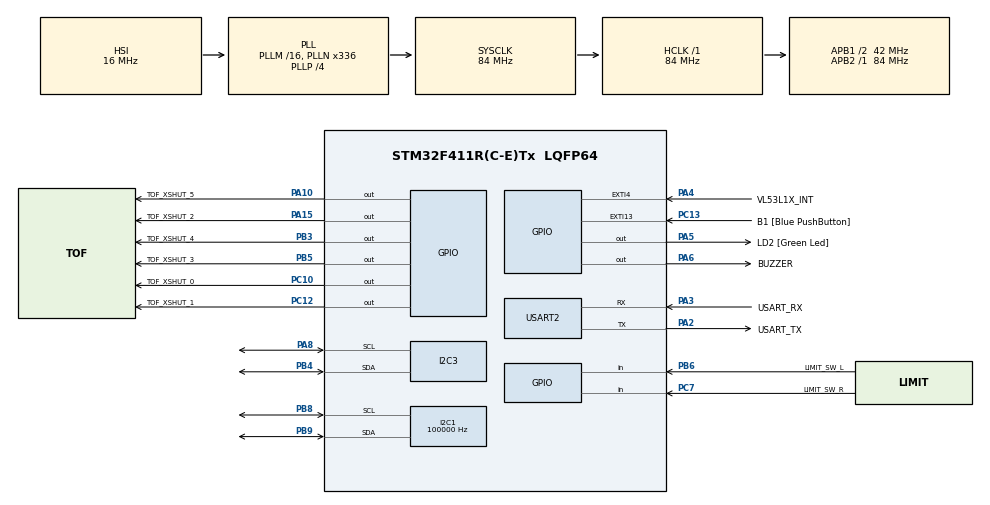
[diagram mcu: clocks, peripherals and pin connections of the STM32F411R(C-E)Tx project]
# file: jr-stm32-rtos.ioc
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Dma.Request0=USART2_RX
Dma.USART2_RX.0.Direction=DMA_PERIPH_TO_MEMORY
Dma.USART2_RX.0.FIFOMode=DMA_FIFOMODE_ENABLE
Dma.USART2_RX.0.FIFOThreshold=DMA_FIFO_THRESHOLD_FULL
Dma.USART2_RX.0.Instance=DMA1_Stream5
Dma.USART2_RX.0.MemBurst=DMA_MBURST_SINGLE
Dma.USART2_RX.0.MemDataAlignment=DMA_MDATAALIGN_BYTE
Dma.USART2_RX.0.MemInc=DMA_MINC_ENABLE
Dma.USART2_RX.0.Mode=DMA_NORMAL
Dma.USART2_RX.0.PeriphBurst=DMA_PBURST_SINGLE
Dma.USART2_RX.0.PeriphDataAlignment=DMA_PDATAALIGN_BYTE
Dma.USART2_RX.0.PeriphInc=DMA_PINC_DISABLE
Dma.USART2_RX.0.Priority=DMA_PRIORITY_LOW
FREERTOS.Tasks01=taskChassis,0,128,chassis_task,Default,NULL,Dynamic,NULL,NULL;taskTOF,0,128,tof_task,Default,NULL,Dynamic,NULL,NULL;taskComm,0,128,comm_task,Default,NULL,Dynamic,NULL,NULL
I2C1.ClockSpeed=100000
I2C1.I2C_Mode=I2C_Standard
Mcu.Family=STM32F4
Mcu.Name=STM32F411R(C-E)Tx
Mcu.Package=LQFP64
NVIC.DMA1_Stream5_IRQn=true\:5\:0\:false\:false\:true\:true\:false\:true
NVIC.PriorityGroup=NVIC_PRIORITYGROUP_4
NVIC.TIM3_IRQn=true\:0\:0\:false\:false\:true\:false\:false\:true
NVIC.TimeBase=TIM3_IRQn
NVIC.TimeBaseIP=TIM3
PA10.GPIO_Label=TOF_XSHUT_5
PA10.Signal=GPIO_Output
PA15.GPIO_Label=TOF_XSHUT_2
PA15.Signal=GPIO_Output
PA2.GPIO_Label=USART_TX
PA2.Mode=Asynchronous
PA2.Signal=USART2_TX
PA3.GPIO_Label=USART_RX
PA3.Mode=Asynchronous
PA3.Signal=USART2_RX
PA4.GPIO_Label=VL53L1X_INT
PA4.GPIO_ModeDefaultEXTI=GPIO_MODE_IT_FALLING
PA4.GPIO_PuPd=GPIO_PULLUP
PA4.Signal=GPXTI4
PA5.GPIO_Label=LD2 [Green Led]
PA5.Signal=GPIO_Output
PA6.GPIO_Label=BUZZER
PA6.Signal=GPIO_Output
PA8.Mode=I2C
PA8.Signal=I2C3_SCL
PB3.GPIO_Label=TOF_XSHUT_4
PB3.Signal=GPIO_Output
PB4.Mode=I2C
PB4.Signal=I2C3_SDA
PB5.GPIO_Label=TOF_XSHUT_3
PB5.Signal=GPIO_Output
PB6.GPIO_Label=LIMIT_SW_L
PB6.GPIO_PuPd=GPIO_PULLUP
PB6.Signal=GPIO_Input
PB8.Mode=I2C
PB8.Signal=I2C1_SCL
PB9.Mode=I2C
PB9.Signal=I2C1_SDA
PC10.GPIO_Label=TOF_XSHUT_0
PC10.Signal=GPIO_Output
PC12.GPIO_Label=TOF_XSHUT_1
PC12.Signal=GPIO_Output
PC13-ANTI_TAMP.GPIO_Label=B1 [Blue PushButton]
PC13-ANTI_TAMP.GPIO_ModeDefaultEXTI=GPIO_MODE_IT_FALLING
PC13-ANTI_TAMP.Signal=GPXTI13
PC14-OSC32_IN.Signal=RCC_OSC32_IN
PC15-OSC32_OUT.Signal=RCC_OSC32_OUT
PC7.GPIO_Label=LIMIT_SW_R
PC7.GPIO_PuPd=GPIO_PULLUP
PC7.Signal=GPIO_Input
PH0\ -\ OSC_IN.Signal=RCC_OSC_IN
PH1\ -\ OSC_OUT.Signal=RCC_OSC_OUT
ProjectManager.HeapSize=0x200
ProjectManager.StackSize=0x400
ProjectManager.TargetToolchain=MDK-ARM V5
RCC.48MHZClocksFreq_Value=84000000
RCC.AHBFreq_Value=84000000
RCC.APB1CLKDivider=RCC_HCLK_DIV2
RCC.APB1Freq_Value=42000000
RCC.APB1TimFreq_Value=84000000
RCC.APB2Freq_Value=84000000
RCC.APB2TimFreq_Value=84000000
RCC.CortexFreq_Value=84000000
RCC.FLatency-AdvancedSettings=FLASH_LATENCY_2
RCC.HCLKFreq_Value=84000000
RCC.HSE_VALUE=8000000
RCC.HSI_VALUE=16000000
RCC.LSE_VALUE=32768
RCC.PLLN=336
RCC.PLLP=RCC_PLLP_DIV4
RCC.SYSCLKFreq_VALUE=84000000
RCC.SYSCLKSource=RCC_SYSCLKSOURCE_PLLCLK
RCC.VCOOutputFreq_Value=336000000
USART2.VirtualMode=VM_ASYNC
VP_FREERTOS_VS_CMSIS_V1.Mode=CMSIS_V1
VP_SYS_VS_tim3.Mode=TIM3
board=NUCLEO-F411RE

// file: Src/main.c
/* USER CODE BEGIN Header */
/**
  ******************************************************************************
  * @file           : main.c
  * @brief          : Main program body
  ******************************************************************************
  * @attention
  *
  * <h2><center>&copy; Copyright (c) 2019 STMicroelectronics.
  * All rights reserved.</center></h2>
  *
  * This software component is licensed by ST under Ultimate Liberty license
  * SLA0044, the "License"; You may not use this file except in compliance with
  * the License. You may obtain a copy of the License at:
  *                             www.st.com/SLA0044
  *
  ******************************************************************************
  */
/* USER CODE END Header */

#include "stm32xxx_hal.h"

#include "main.h"
#include "stdio.h"
#include "cmsis_os.h"
#include "chassis_task.h"
#include "comm_task.h"
#include "tof_task.h"
#include "sys_config.h"
#include "buzzer.h"
#include "MeEncoderNew.h"

I2C_HandleTypeDef hi2c1;
I2C_HandleTypeDef hi2c3;

UART_HandleTypeDef huart2;
DMA_HandleTypeDef hdma_usart2_rx;
DMA_HandleTypeDef hdma_usart2_tx;

osThreadId taskChassisHandle;
osThreadId taskTOFHandle;
osThreadId taskCommHandle;

void SystemClock_Config(void);
static void MX_GPIO_Init(void);
static void MX_DMA_Init(void);
static void MX_USART2_UART_Init(void);
static void MX_I2C1_Init(void);
static void MX_I2C3_Init(void);

/* USER CODE BEGIN 0 */
#define PUTCHAR_PROTOTYPE int fputc(int ch, FILE *f)

/* Debug print message redirect to huart interface */
PUTCHAR_PROTOTYPE
{
	HAL_UART_Transmit(&COMPUTER_HUART, (uint8_t*)&ch, 1, 0xFFFF);
  return ch;
}

/* USER CODE END 0 */

int main(void)
{

  /* MCU Configuration--------------------------------------------------------*/

  /* Reset of all peripherals, Initializes the Flash interface and the Systick. */
  HAL_Init();

  /* Configure the system clock */
  SystemClock_Config();

  /* Initialize all configured peripherals */
  MX_GPIO_Init();
  MX_DMA_Init();
  MX_USART2_UART_Init();
  MX_I2C1_Init();
	//__HAL_RCC_I2C1_FORCE_RESET();
	//HAL_Delay(2);
	//__HAL_RCC_I2C1_RELEASE_RESET();
	HAL_Delay(200);

  MX_I2C3_Init();

	//XNUCLEO53L1A1_Init();

	/* Initialize MeEncoder Driver */
	MeEncoderNew_Init();

	/* Initialize TOF sensors */
	VL53L1_TOF_Config();
	VL53L1_TOF_Init();

	/* USER CODE BEGIN 2 */
	communicate_param_init();

  /* USER CODE END 2 */

  /* Create the thread(s) */
  /* definition and creation of taskChassis */
  osThreadDef(taskChassis, chassis_task, osPriorityHigh, 0, 128);
  taskChassisHandle = osThreadCreate(osThread(taskChassis), NULL);

  /* definition and creation of taskTOF */
  osThreadDef(taskTOF, tof_task, osPriorityHigh, 0, 256);
  taskTOFHandle = osThreadCreate(osThread(taskTOF), NULL);

  /* definition and creation of taskComm */
  osThreadDef(taskComm, comm_task, osPriorityHigh, 0, 128);
  taskCommHandle = osThreadCreate(osThread(taskComm), NULL);

	buzz_n_times_with_delay(2, 100);

  /* Start scheduler */
  osKernelStart();

  /* We should never get here as control is now taken by the scheduler */

  /* Infinite loop */
  while (1)
  {

  }
}

void SystemClock_Config(void)
{
  RCC_OscInitTypeDef RCC_OscInitStruct = {0};
  RCC_ClkInitTypeDef RCC_ClkInitStruct = {0};

  /** Configure the main internal regulator output voltage
  */
  __HAL_RCC_PWR_CLK_ENABLE();
  __HAL_PWR_VOLTAGESCALING_CONFIG(PWR_REGULATOR_VOLTAGE_SCALE1);
  /** Initializes the CPU, AHB and APB busses clocks
  */
  RCC_OscInitStruct.OscillatorType = RCC_OSCILLATORTYPE_HSI;
  RCC_OscInitStruct.HSIState = RCC_HSI_ON;
  RCC_OscInitStruct.HSICalibrationValue = RCC_HSICALIBRATION_DEFAULT;
  RCC_OscInitStruct.PLL.PLLState = RCC_PLL_ON;
  RCC_OscInitStruct.PLL.PLLSource = RCC_PLLSOURCE_HSI;
  RCC_OscInitStruct.PLL.PLLM = 16;
  RCC_OscInitStruct.PLL.PLLN = 336;
  RCC_OscInitStruct.PLL.PLLP = RCC_PLLP_DIV4;
  RCC_OscInitStruct.PLL.PLLQ = 4;
  if (HAL_RCC_OscConfig(&RCC_OscInitStruct) != HAL_OK)
  {
    Error_Handler();
  }
  /** Initializes the CPU, AHB and APB busses clocks
  */
  RCC_ClkInitStruct.ClockType = RCC_CLOCKTYPE_HCLK|RCC_CLOCKTYPE_SYSCLK
                              |RCC_CLOCKTYPE_PCLK1|RCC_CLOCKTYPE_PCLK2;
  RCC_ClkInitStruct.SYSCLKSource = RCC_SYSCLKSOURCE_PLLCLK;
  RCC_ClkInitStruct.AHBCLKDivider = RCC_SYSCLK_DIV1;
  RCC_ClkInitStruct.APB1CLKDivider = RCC_HCLK_DIV2;
  RCC_ClkInitStruct.APB2CLKDivider = RCC_HCLK_DIV1;

  if (HAL_RCC_ClockConfig(&RCC_ClkInitStruct, FLASH_LATENCY_2) != HAL_OK)
  {
    Error_Handler();
  }
}

static void MX_I2C1_Init(void)
{

  hi2c1.Instance = I2C1;
  hi2c1.Init.ClockSpeed = 100000; //100000;
  hi2c1.Init.DutyCycle = I2C_DUTYCYCLE_2;
  hi2c1.Init.OwnAddress1 = 0;
  hi2c1.Init.AddressingMode = I2C_ADDRESSINGMODE_7BIT;
  hi2c1.Init.DualAddressMode = I2C_DUALADDRESS_DISABLE;
  hi2c1.Init.OwnAddress2 = 0;
  hi2c1.Init.GeneralCallMode = I2C_GENERALCALL_DISABLE;
  hi2c1.Init.NoStretchMode = I2C_NOSTRETCH_DISABLE;
  if (HAL_I2C_Init(&hi2c1) != HAL_OK)
  {
    Error_Handler();
  }

}

static void MX_I2C3_Init(void)
{

  hi2c3.Instance = I2C3;
  hi2c3.Init.ClockSpeed = 100000;
  hi2c3.Init.DutyCycle = I2C_DUTYCYCLE_2;
  hi2c3.Init.OwnAddress1 = 0;
  hi2c3.Init.AddressingMode = I2C_ADDRESSINGMODE_7BIT;
  hi2c3.Init.DualAddressMode = I2C_DUALADDRESS_DISABLE;
  hi2c3.Init.OwnAddress2 = 0;
  hi2c3.Init.GeneralCallMode = I2C_GENERALCALL_DISABLE;
  hi2c3.Init.NoStretchMode = I2C_NOSTRETCH_DISABLE;
  if (HAL_I2C_Init(&hi2c3) != HAL_OK)
  {
    Error_Handler();
  }

}

static void MX_USART2_UART_Init(void)
{

  huart2.Instance = USART2;
  huart2.Init.BaudRate = 115200;
  huart2.Init.WordLength = UART_WORDLENGTH_8B;
  huart2.Init.StopBits = UART_STOPBITS_1;
  huart2.Init.Parity = UART_PARITY_NONE;
  huart2.Init.Mode = UART_MODE_TX_RX;
  huart2.Init.HwFlowCtl = UART_HWCONTROL_NONE;
  huart2.Init.OverSampling = UART_OVERSAMPLING_16;
  if (HAL_UART_Init(&huart2) != HAL_OK)
  {
    Error_Handler();
  }

}

static void MX_DMA_Init(void)
{
  /* DMA controller clock enable */
  __HAL_RCC_DMA1_CLK_ENABLE();

  /* DMA interrupt init */
  /* DMA1_Stream5_IRQn interrupt configuration */
  HAL_NVIC_SetPriority(DMA1_Stream5_IRQn, 5, 0);
  HAL_NVIC_EnableIRQ(DMA1_Stream5_IRQn);

}

static void MX_GPIO_Init(void)
{
  GPIO_InitTypeDef GPIO_InitStruct = {0};

  /* GPIO Ports Clock Enable */
  __HAL_RCC_GPIOC_CLK_ENABLE();
  __HAL_RCC_GPIOH_CLK_ENABLE();
  __HAL_RCC_GPIOA_CLK_ENABLE();
  __HAL_RCC_GPIOB_CLK_ENABLE();

  /*Configure GPIO pin Output Level */
  HAL_GPIO_WritePin(GPIOA, LD2_Pin|TOF_XSHUT_5_Pin|TOF_XSHUT_0_Pin|TOF_XSHUT_1_Pin
                          |TOF_XSHUT_2_Pin, GPIO_PIN_RESET);

  /*Configure GPIO pin Output Level */
  HAL_GPIO_WritePin(GPIOB, TOF_XSHUT_4_Pin|TOF_XSHUT_3_Pin, GPIO_PIN_RESET);

  /*Configure GPIO pin : B1_Pin */
  GPIO_InitStruct.Pin = B1_Pin;
  GPIO_InitStruct.Mode = GPIO_MODE_IT_FALLING;
  GPIO_InitStruct.Pull = GPIO_NOPULL;
  HAL_GPIO_Init(B1_GPIO_Port, &GPIO_InitStruct);

  /*Configure GPIO pin : VL53L1X_INT_Pin */
  GPIO_InitStruct.Pin = VL53L1X_INT_Pin;
  GPIO_InitStruct.Mode = GPIO_MODE_IT_FALLING;
  GPIO_InitStruct.Pull = GPIO_PULLUP;
  HAL_GPIO_Init(VL53L1X_INT_GPIO_Port, &GPIO_InitStruct);

  /*Configure GPIO pins : LD2_Pin */
  GPIO_InitStruct.Pin = LD2_Pin;
  GPIO_InitStruct.Mode = GPIO_MODE_OUTPUT_PP;
  GPIO_InitStruct.Pull = GPIO_NOPULL;
  GPIO_InitStruct.Speed = GPIO_SPEED_FREQ_LOW;
  HAL_GPIO_Init(GPIOA, &GPIO_InitStruct);

  /*Configure GPIO pins : LIMIT_SW_L_Pin LIMIT_SW_R_Pin */
  GPIO_InitStruct.Pin = LIMIT_SW_R_Pin;
  GPIO_InitStruct.Mode = GPIO_MODE_INPUT;
  GPIO_InitStruct.Pull = GPIO_PULLUP;
  HAL_GPIO_Init(LIMIT_SW_R_GPIO_Port, &GPIO_InitStruct);

	GPIO_InitStruct.Pin = LIMIT_SW_L_Pin;
  GPIO_InitStruct.Mode = GPIO_MODE_INPUT;
  GPIO_InitStruct.Pull = GPIO_PULLUP;
  HAL_GPIO_Init(LIMIT_SW_L_GPIO_Port, &GPIO_InitStruct);

	/* Configure GPIO pins : BUZZER */
	GPIO_InitStruct.Pin = BUZZER_Pin;
  GPIO_InitStruct.Mode = GPIO_MODE_OUTPUT_PP;
  GPIO_InitStruct.Pull = GPIO_NOPULL;
  GPIO_InitStruct.Speed = GPIO_SPEED_FREQ_LOW;
  HAL_GPIO_Init(BUZZER_GPIO_Port, &GPIO_InitStruct);
}

void HAL_TIM_PeriodElapsedCallback(TIM_HandleTypeDef *htim)
{
  if (htim->Instance == TIM3) {
    HAL_IncTick();
  }
}

void Error_Handler(void)
{
}

/************************ (C) COPYRIGHT STMicroelectronics *****END OF FILE****/
